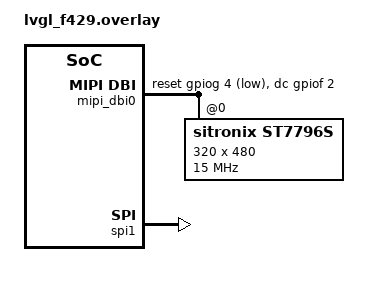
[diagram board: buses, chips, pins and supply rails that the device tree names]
/* ST7796S 320x480 on SPI1, pins from 02-pin-maps.md for f429 (SPI1: PA5 SCK, PA6 MISO, PA7 MOSI) */
#include <zephyr/dt-bindings/mipi_dbi/mipi_dbi.h>
#include <zephyr/dt-bindings/spi/spi.h>

/ {
	chosen {
		zephyr,display = &st7796s;
	};

	mipi_dbi0: mipi_dbi {
		compatible = "zephyr,mipi-dbi-spi";
		spi-dev = <&spi1>;
		dc-gpios = <&gpiof 2 GPIO_ACTIVE_HIGH>;
		reset-gpios = <&gpiog 4 GPIO_ACTIVE_LOW>;
		write-only;
		#address-cells = <1>;
		#size-cells = <0>;

		st7796s: st7796s@0 {
			compatible = "sitronix,st7796s";
			reg = <0>;
			mipi-max-frequency = <15000000>;
			mipi-mode = "MIPI_DBI_MODE_SPI_4WIRE";
			width = <320>;
			height = <480>;
			/* gamma tables copied from Zephyr's lcd_par_s035 shield: PLACEHOLDERS, must be
			 * replaced with the values for the real panel before use on hardware */
			pgc = [f0 06 0b 07 06 05 2e 33 47 3a 17 16 2e 31];
			ngc = [f0 09 0d 09 08 23 2e 33 46 38 13 13 2c 32];
		};
	};
};

&spi1 {
	status = "okay";
	cs-gpios = <&gpiod 13 GPIO_ACTIVE_LOW>;
};
